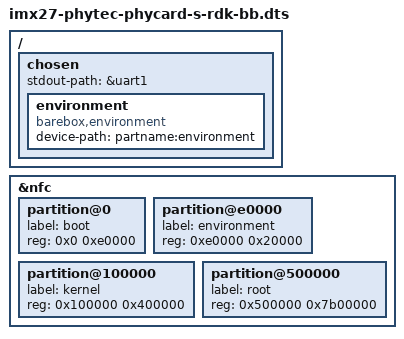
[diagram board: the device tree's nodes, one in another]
/*
 * Barebox specific DT overlay for Phytec PCA100 RDK
 */

#include <arm/imx27-phytec-phycard-s-rdk.dts>

/ {
	chosen {
		stdout-path = &uart1;

		environment {
			compatible = "barebox,environment";
			device-path = &nfc, "partname:environment";
		};
	};
};

&nfc {
	partition@0 {
		label = "boot";
		reg = <0x0 0xe0000>;
	};

	partition@e0000 {
		label = "environment";
		reg = <0xe0000 0x20000>;
	};

	partition@100000 {
		label = "kernel";
		reg = <0x100000 0x400000>;
	};

	partition@500000 {
		label = "root";
		reg = <0x500000 0x7b00000>;
	};
};
